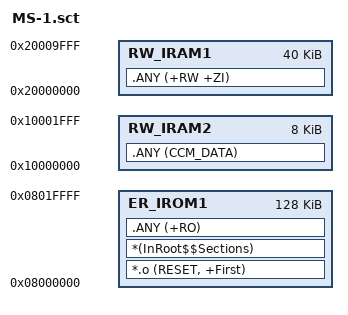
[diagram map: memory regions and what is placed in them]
; *************************************************************
; *** Scatter-Loading Description File generated by uVision ***
; *************************************************************

LR_IROM1 0x08000000 0x00020000  {    ; load region size_region
  ER_IROM1 0x08000000 0x00020000  {  ; load address = execution address
   *.o (RESET, +First)
   *(InRoot$$Sections)
   .ANY (+RO)
  }
  RW_IRAM1 0x20000000 0x0000A000  {  ; RW data
   .ANY (+RW +ZI)
  }
  RW_IRAM2 0x10000000 0x00002000  {  ; CCM data
   .ANY (CCM_DATA)
   ;startup_stm32f437xx.o (STACK)
   ;startup_stm32f437xx.o (HEAP)	;FOO ccmFoo[1024] __attribute__ ((section("CCM_DATA")));
  }
}
